# PIC18F55Q43 register map
Vendor: Microchip
Registers are 8-bit, read-write, reset 0x0 unless marked. A register's access mark holds for its fields unless they carry their own. Addresses are absolute, and some are shared; only a register's first bit layout is shown; [hi:lo] are bit positions; {n}, {i} and the like mark numbered series.

## SFR
0x40 NVMCON0 reset not defined — (power-on value -------x)
  [0] GO
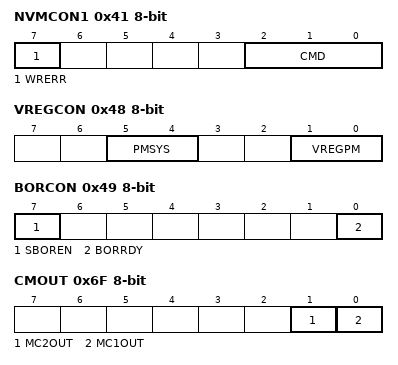
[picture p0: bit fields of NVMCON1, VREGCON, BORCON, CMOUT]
0x41 NVMCON1 reset not defined — (power-on value x----xxx)
  [7] WRERR, [2:0] CMD
0x42 NVMLOCK
  [7:0] LOCK
0x43 NVMADRL
0x44 NVMADRH
0x45 NVMADRU
  [5:0] NVMADRU
0x46 NVMDATL
0x47 NVMDATH
0x48 VREGCON reset not defined — (power-on value --qq--10)
  [5:4] PMSYS ro, [1:0] VREGPM
0x49 BORCON reset not defined — (power-on value 1------q)
  [7] SBOREN, [0] BORRDY ro
0x6F CMOUT ro
  [1] MC2OUT, [0] MC1OUT
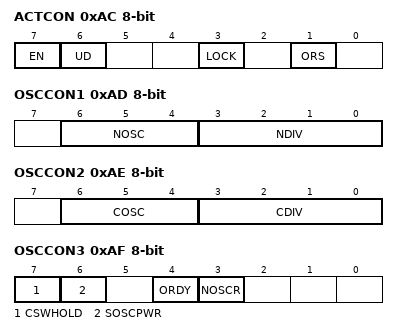
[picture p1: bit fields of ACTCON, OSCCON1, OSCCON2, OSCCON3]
0xAC ACTCON
  [7] EN, [6] UD, [3] LOCK ro, [1] ORS ro
0xAD OSCCON1 reset not defined — (power-on value -qqqqqqq)
  [6:4] NOSC, [3:0] NDIV
0xAE OSCCON2 ro reset not defined — (power-on value -qqqqqqq)
  [6:4] COSC, [3:0] CDIV
0xAF OSCCON3
  [7] CSWHOLD, [6] SOSCPWR, [4] ORDY ro, [3] NOSCR ro
0xB0 OSCTUNE
  [5:0] TUN
0xB1 OSCFRQ reset not defined — (power-on value ----q0q0)
  [3:0] HFFRQ
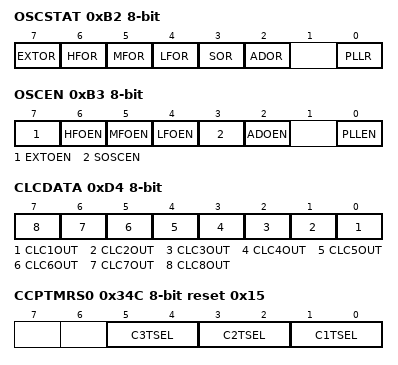
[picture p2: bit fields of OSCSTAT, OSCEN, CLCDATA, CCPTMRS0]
0xB2 OSCSTAT ro reset not defined — (power-on value qqqqqq-q)
  [7] EXTOR, [6] HFOR, [5] MFOR, [4] LFOR, [3] SOR, [2] ADOR, [0] PLLR
0xB3 OSCEN
  [7] EXTOEN, [6] HFOEN, [5] MFOEN, [4] LFOEN, [3] SOSCEN, [2] ADOEN, [0] PLLEN
0xB4 PRLOCK
  [0] PRLOCKED
0xB5 SCANPR reset 0x7
  [2:0] PR
{0xB5+i} DMA{i}PR reset 0x7 (i=1..6)
  [2:0] PR
0xBE MAINPR reset 0x7
  [2:0] PR
0xBF ISRPR reset 0x7
  [2:0] PR
0xD4 CLCDATA
  [n-1] CLC{n}OUT (n=1..8)
0x200 PPSLOCK
  [0] PPSLOCKED
0x34C CCPTMRS0 reset 0x15
  [5:4] C3TSEL, [3:2] C2TSEL, [1:0] C1TSEL
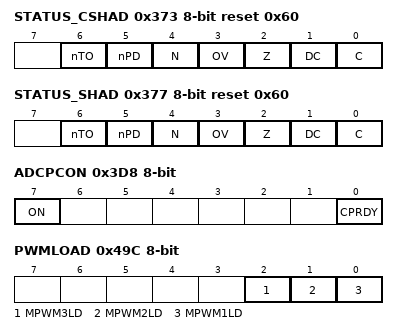
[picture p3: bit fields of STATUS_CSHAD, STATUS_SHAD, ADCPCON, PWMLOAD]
0x373 STATUS_CSHAD reset 0x60
  [6] nTO ro, [5] nPD ro, [4] N, [3] OV, [2] Z, [1] DC, [0] C
0x374 WREG_CSHAD reset not defined — (power-on value xxxxxxxx)
  [7:0] WREG
0x375 BSR_CSHAD
  [5:0] BSR
0x376 SHADCON
  [0] SHADLO
0x377 STATUS_SHAD reset 0x60
  [6] nTO ro, [5] nPD ro, [4] N, [3] OV, [2] Z, [1] DC, [0] C
0x378 WREG_SHAD reset not defined — (power-on value xxxxxxxx)
  [7:0] WREG
0x379 BSR_SHAD
  [5:0] BSR
0x37A PCLATH_SHAD
  [7:0] PCH
0x37B PCLATU_SHAD
  [4:0] PCU
{0x37C+2i} FSR{i}L_SHAD (i=0..2)
  [7:0] FSR{i}L
{0x37D+2i} FSR{i}H_SHAD (i=0..2)
  [5:0] FSR{i}H
0x382 PRODL_SHAD reset not defined — (power-on value xxxxxxxx)
  [7:0] PRODL
0x383 PRODH_SHAD reset not defined — (power-on value xxxxxxxx)
  [7:0] PRODH
0x3D8 ADCPCON reset not defined — (power-on value x------x)
  [7] ON, [0] CPRDY ro
0x49C PWMLOAD
  [2] MPWM3LD, [1] MPWM2LD, [0] MPWM1LD
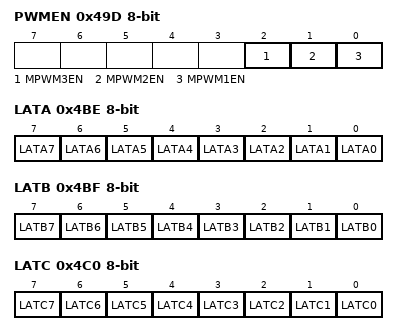
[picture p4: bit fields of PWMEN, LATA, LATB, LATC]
0x49D PWMEN
  [2] MPWM3EN, [1] MPWM2EN, [0] MPWM1EN
0x4BE LATA reset not defined — (power-on value xxxxxxxx)
  [n] LATA{n} (n=0..7)
0x4BF LATB reset not defined — (power-on value xxxxxxxx)
  [n] LATB{n} (n=0..7)
0x4C0 LATC reset not defined — (power-on value xxxxxxxx)
  [n] LATC{n} (n=0..7)
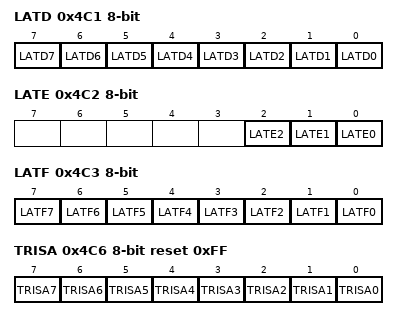
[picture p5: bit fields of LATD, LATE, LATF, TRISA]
0x4C1 LATD reset not defined — (power-on value xxxxxxxx)
  [n] LATD{n} (n=0..7)
0x4C2 LATE reset not defined — (power-on value -----xxx)
  [2] LATE2, [1] LATE1, [0] LATE0
0x4C3 LATF reset not defined — (power-on value xxxxxxxx)
  [n] LATF{n} (n=0..7)
0x4C6 TRISA reset 0xFF
  [n] TRISA{n} (n=0..7)
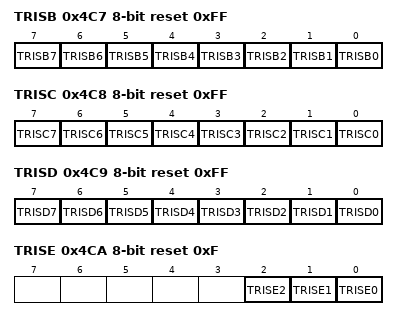
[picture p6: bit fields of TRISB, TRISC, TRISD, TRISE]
0x4C7 TRISB reset 0xFF
  [n] TRISB{n} (n=0..7)
0x4C8 TRISC reset 0xFF
  [n] TRISC{n} (n=0..7)
0x4C9 TRISD reset 0xFF
  [n] TRISD{n} (n=0..7)
0x4CA TRISE reset 0xF
  [2] TRISE2, [1] TRISE1, [0] TRISE0
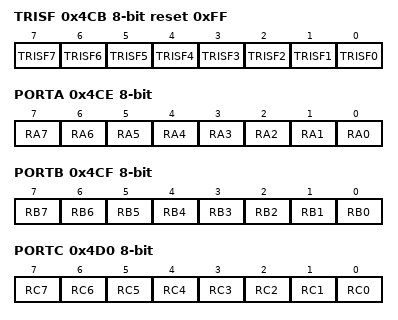
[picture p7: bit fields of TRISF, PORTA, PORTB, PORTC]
0x4CB TRISF reset 0xFF
  [n] TRISF{n} (n=0..7)
0x4CE PORTA reset not defined — (power-on value xxxxxxxx)
  [n] RA{n} (n=0..7)
0x4CF PORTB reset not defined — (power-on value xxxxxxxx)
  [n] RB{n} (n=0..7)
0x4D0 PORTC reset not defined — (power-on value xxxxxxxx)
  [n] RC{n} (n=0..7)
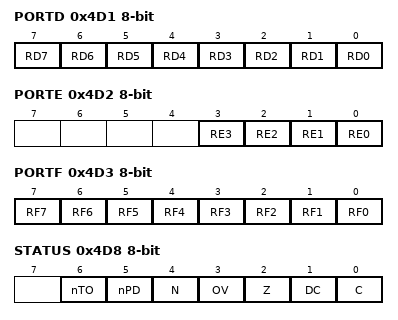
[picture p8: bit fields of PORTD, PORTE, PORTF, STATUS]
0x4D1 PORTD reset not defined — (power-on value xxxxxxxx)
  [n] RD{n} (n=0..7)
0x4D2 PORTE reset not defined — (power-on value ----xxxx)
  [3] RE3 ro, [2] RE2, [1] RE1, [0] RE0
0x4D3 PORTF reset not defined — (power-on value xxxxxxxx)
  [n] RF{n} (n=0..7)
0x4D8 STATUS reset not defined — (power-on value -xxxxxxx)
  [6] nTO, [5] nPD, [4] N, [3] OV, [2] Z, [1] DC, [0] C
0x4D9 FSR2L
0x4DA FSR2H
  [5:0] FSR2H
0x4DB PLUSW2 access not given reset not defined
0x4DC PREINC2 access not given reset not defined
0x4DD POSTDEC2 access not given reset not defined
0x4DE POSTINC2 access not given reset not defined
0x4DF INDF2 access not given reset not defined — (power-on value xxxxxxxx)
0x4E0 BSR
  [5:0] BSR
0x4E1 FSR1L
0x4E2 FSR1H
  [5:0] FSR1H
0x4E3 PLUSW1 access not given reset not defined
0x4E4 PREINC1 access not given reset not defined
0x4E5 POSTDEC1 access not given reset not defined
0x4E6 POSTINC1 access not given reset not defined
0x4E7 INDF1 access not given reset not defined — (power-on value xxxxxxxx)
0x4E8 WREG reset not defined — (power-on value xxxxxxxx)
0x4E9 FSR0L
0x4EA FSR0H
  [5:0] FSR0H
0x4EB PLUSW0 access not given reset not defined
0x4EC PREINC0 access not given reset not defined
0x4ED POSTDEC0 access not given reset not defined
0x4EE POSTINC0 access not given reset not defined
0x4EF INDF0 access not given reset not defined — (power-on value xxxxxxxx)
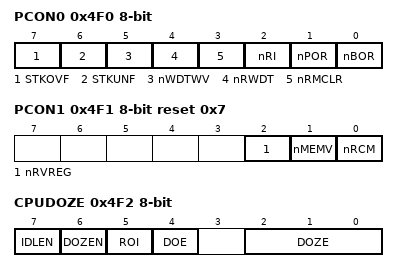
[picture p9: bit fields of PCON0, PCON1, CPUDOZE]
0x4F0 PCON0 reset not defined — (power-on value 0011110q)
  [7] STKOVF, [6] STKUNF, [5] nWDTWV, [4] nRWDT, [3] nRMCLR, [2] nRI, [1] nPOR, [0] nBOR
0x4F1 PCON1 reset 0x7
  [2] nRVREG, [1] nMEMV, [0] nRCM
0x4F2 CPUDOZE
  [7] IDLEN, [6] DOZEN, [5] ROI, [4] DOE, [2:0] DOZE
0x4F3 PRODL reset not defined — (power-on value xxxxxxxx)
0x4F4 PRODH reset not defined — (power-on value xxxxxxxx)
0x4F5 TABLAT
0x4F6 TBLPTRL
0x4F7 TBLPTRH
0x4F8 TBLPTRU
  [5:0] TBLPTRU
0x4F9 PCL
0x4FA PCLATH
  [7:0] PCH
0x4FB PCLATU
  [4:0] PCU
0x4FC STKPTR
  [5:0] STKPTR
0x4FD TOSL reset not defined — (power-on value xxxxxxxx)
0x4FE TOSH reset not defined — (power-on value xxxxxxxx)
0x4FF TOSU reset not defined — (power-on value ---xxxxx)
  [4:0] TOSU
